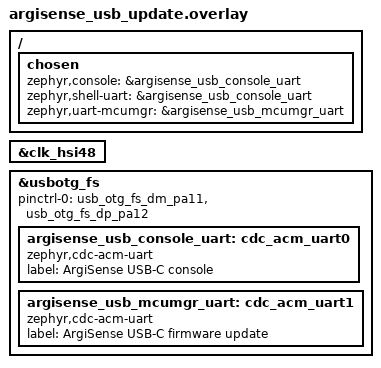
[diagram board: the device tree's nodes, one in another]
/*
 * SPDX-License-Identifier: Apache-2.0
 *
 * USB-C composite profile:
 * - CDC ACM 0: Zephyr console, log output, and shell.
 * - CDC ACM 1: MCUmgr SMP firmware update transport.
 */

/ {
	chosen {
		zephyr,console = &argisense_usb_console_uart;
		zephyr,shell-uart = &argisense_usb_console_uart;
		zephyr,uart-mcumgr = &argisense_usb_mcumgr_uart;
	};
};

&clk_hsi48 {
	status = "okay";
};

zephyr_udc0: &usbotg_fs {
	pinctrl-0 = <&usb_otg_fs_dm_pa11 &usb_otg_fs_dp_pa12>;
	pinctrl-names = "default";
	status = "okay";

	argisense_usb_console_uart: cdc_acm_uart0 {
		compatible = "zephyr,cdc-acm-uart";
		label = "ArgiSense USB-C console";
	};

	argisense_usb_mcumgr_uart: cdc_acm_uart1 {
		compatible = "zephyr,cdc-acm-uart";
		label = "ArgiSense USB-C firmware update";
	};
};
